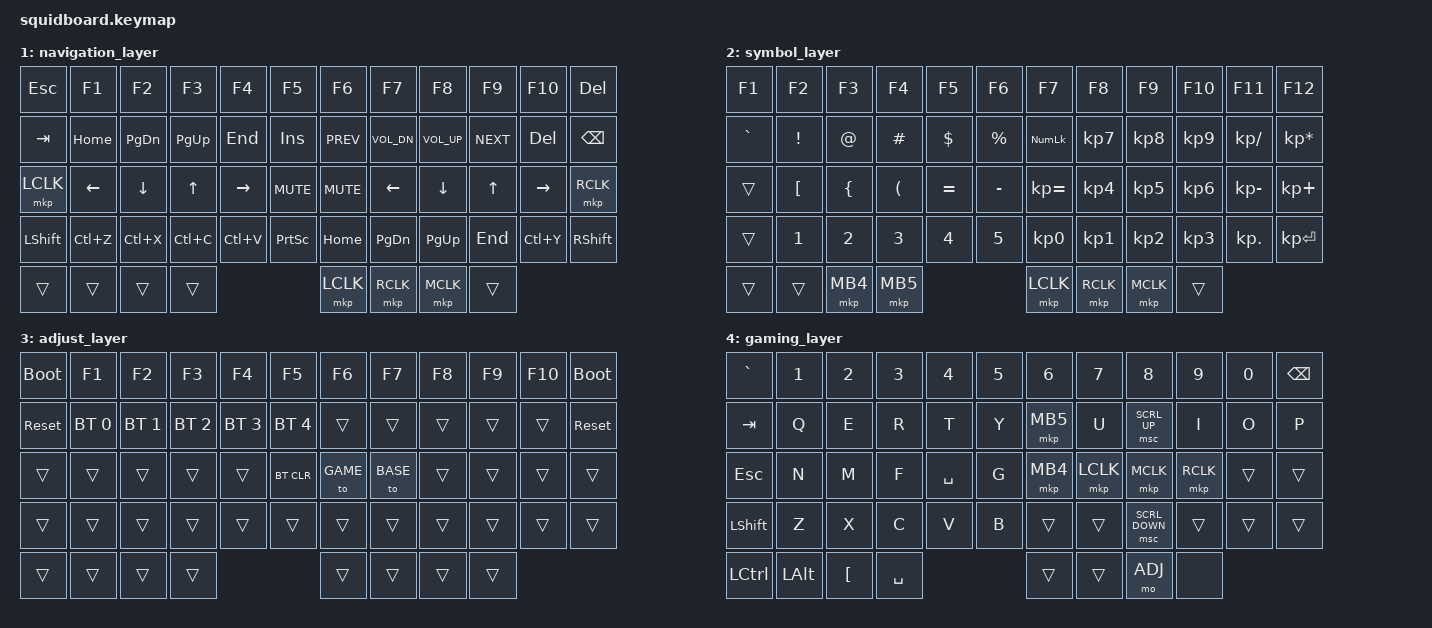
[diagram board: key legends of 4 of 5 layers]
#include <behaviors.dtsi>
#include <dt-bindings/zmk/bt.h>
#include <dt-bindings/zmk/keys.h>
#include <dt-bindings/zmk/pointing.h>
#include <input/processors.dtsi>

#define BASE 0
#define NAV  1
#define SYM  2
#define ADJ  3
#define GAME 4

#define HRML(k1, k2, k3, k4) &hml LGUI k1  &hml LALT k2  &hml LCTRL k3  &hml LSHFT k4
#define HRMR(k1, k2, k3, k4) &hmr RSHFT k1 &hmr RCTRL k2 &hmr RALT k3  &hmr RGUI k4

/ {
    joystick_wasd: joystick_wasd {
        compatible = "zmk,input-processor-joystick-wasd";
        #input-processor-cells = <0>;
        bindings = <&kp W>, <&kp S>, <&kp A>, <&kp D>;
        threshold = <8>;
        release-after-ms = <50>;
    };

    behaviors {
        hml: home_row_mod_left {
            compatible = "zmk,behavior-hold-tap";
            #binding-cells = <2>;
            flavor = "tap-preferred";
            tapping-term-ms = <240>;
            quick-tap-ms = <175>;
            require-prior-idle-ms = <125>;
            bindings = <&kp>, <&kp>;
        };

        hmr: home_row_mod_right {
            compatible = "zmk,behavior-hold-tap";
            #binding-cells = <2>;
            flavor = "tap-preferred";
            tapping-term-ms = <240>;
            quick-tap-ms = <175>;
            require-prior-idle-ms = <125>;
            bindings = <&kp>, <&kp>;
        };
    };

    conditional_layers {
        compatible = "zmk,conditional-layers";

        adjust_layer {
            if-layers = <NAV SYM>;
            then-layer = <ADJ>;
        };
    };

    keymap {
        compatible = "zmk,keymap";

        base_layer {
            bindings = <
                &kp GRAVE    &kp N1  &kp N2  &kp N3  &kp N4  &kp N5     &kp N6  &kp N7  &kp N8     &kp N9   &kp N0    &kp BSPC
                &kp TAB    &kp Q   &kp W   &kp E   &kp R   &kp T      &kp Y   &kp U   &kp I      &kp O    &kp P     &kp BSLH
                &kp ESC HRML(A, S, D, F)          &kp G              &kp H   HRMR(J, K, L, SEMI)          &kp SQT
                &kp LSHFT  &kp Z   &kp X   &kp C   &kp V   &kp B      &kp N   &kp M   &kp COMMA  &kp DOT  &kp FSLH  &kp ENTER
                &kp LCTRL  &mo NAV &kp LBKT &kp SPACE                  &kp SPACE &kp RBKT &mo ADJ &mo SYM
            >;
        };

        navigation_layer {
            bindings = <
                &kp ESC   &kp F1    &kp F2    &kp F3    &kp F4      &kp F5       &kp F6     &kp F7    &kp F8    &kp F9    &kp F10   &kp DEL
                &kp TAB   &kp HOME  &kp PG_DN &kp PG_UP &kp END     &kp INS      &kp C_PREV &kp C_VOL_DN &kp C_VOL_UP &kp C_NEXT &kp DEL &kp BSPC
                &mkp LCLK &kp LEFT  &kp DOWN  &kp UP    &kp RIGHT   &kp C_MUTE   &kp C_MUTE &kp LEFT  &kp DOWN  &kp UP    &kp RIGHT &mkp RCLK
                &kp LSHFT &kp LC(Z) &kp LC(X) &kp LC(C) &kp LC(V)   &kp PSCRN    &kp HOME   &kp PG_DN &kp PG_UP &kp END   &kp LC(Y) &kp RSHFT
                &trans    &trans    &trans    &trans                  &mkp LCLK      &mkp RCLK     &mkp MCLK   &trans
            >;
        };

        symbol_layer {
            bindings = <
                &kp F1    &kp F2   &kp F3   &kp F4   &kp F5    &kp F6      &kp F7   &kp F8   &kp F9   &kp F10  &kp F11  &kp F12
                &kp GRAVE &kp EXCL &kp AT   &kp HASH &kp DLLR  &kp PRCNT   &kp KP_NUM &kp KP_N7 &kp KP_N8 &kp KP_N9 &kp KP_DIVIDE &kp KP_MULTIPLY
                &trans    &kp LBKT &kp LBRC &kp LPAR &kp EQUAL &kp MINUS   &kp KP_EQUAL &kp KP_N4 &kp KP_N5 &kp KP_N6 &kp KP_MINUS &kp KP_PLUS
                &trans    &kp N1   &kp N2   &kp N3   &kp N4    &kp N5      &kp KP_N0 &kp KP_N1 &kp KP_N2 &kp KP_N3 &kp KP_DOT &kp KP_ENTER
                &trans    &trans   &mkp MB4   &mkp MB5                  &mkp LCLK    &mkp RCLK   &mkp MCLK   &trans
            >;
        };

        adjust_layer {
            bindings = <
                &bootloader &kp F1 &kp F2 &kp F3 &kp F4 &kp F5        &kp F6 &kp F7 &kp F8 &kp F9 &kp F10 &bootloader
                &sys_reset  &bt BT_SEL 0 &bt BT_SEL 1 &bt BT_SEL 2 &bt BT_SEL 3 &bt BT_SEL 4  &trans &trans &trans &trans &trans &sys_reset
                &trans      &trans &trans &trans &trans &bt BT_CLR     &to GAME &to BASE &trans &trans &trans &trans
                &trans      &trans &trans &trans &trans &trans         &trans &trans &trans &trans &trans &trans
                &trans      &trans &trans &trans                       &trans &trans &trans &trans
            >;
        };

        gaming_layer {
            bindings = <
                &kp GRAVE &kp N1    &kp N2   &kp N3    &kp N4     &kp N5       &kp N6   &kp N7    &kp N8         &kp N9    &kp N0    &kp BSPC
                &kp TAB   &kp Q     &kp E    &kp R     &kp T      &kp Y        &mkp MB5 &kp U    &msc SCRL_UP   &kp I    &kp O    &kp P
                &kp ESC   &kp N     &kp M    &kp F     &kp SPACE  &kp G        &mkp MB4 &mkp LCLK &mkp MCLK      &mkp RCLK &trans &trans
                &kp LSHFT &kp Z     &kp X    &kp C     &kp V      &kp B        &trans   &trans    &msc SCRL_DOWN &trans    &trans    &trans
                &kp LCTRL &kp LALT  &kp LBKT &kp SPACE                         &trans   &trans    &mo ADJ        &none
            >;
        };
    };
};

&joystick_listener {
    input-processors = <&zip_xy_to_scroll_mapper>;

    gaming_mode {
        layers = <GAME>;
        input-processors = <&joystick_wasd>;
    };
};
